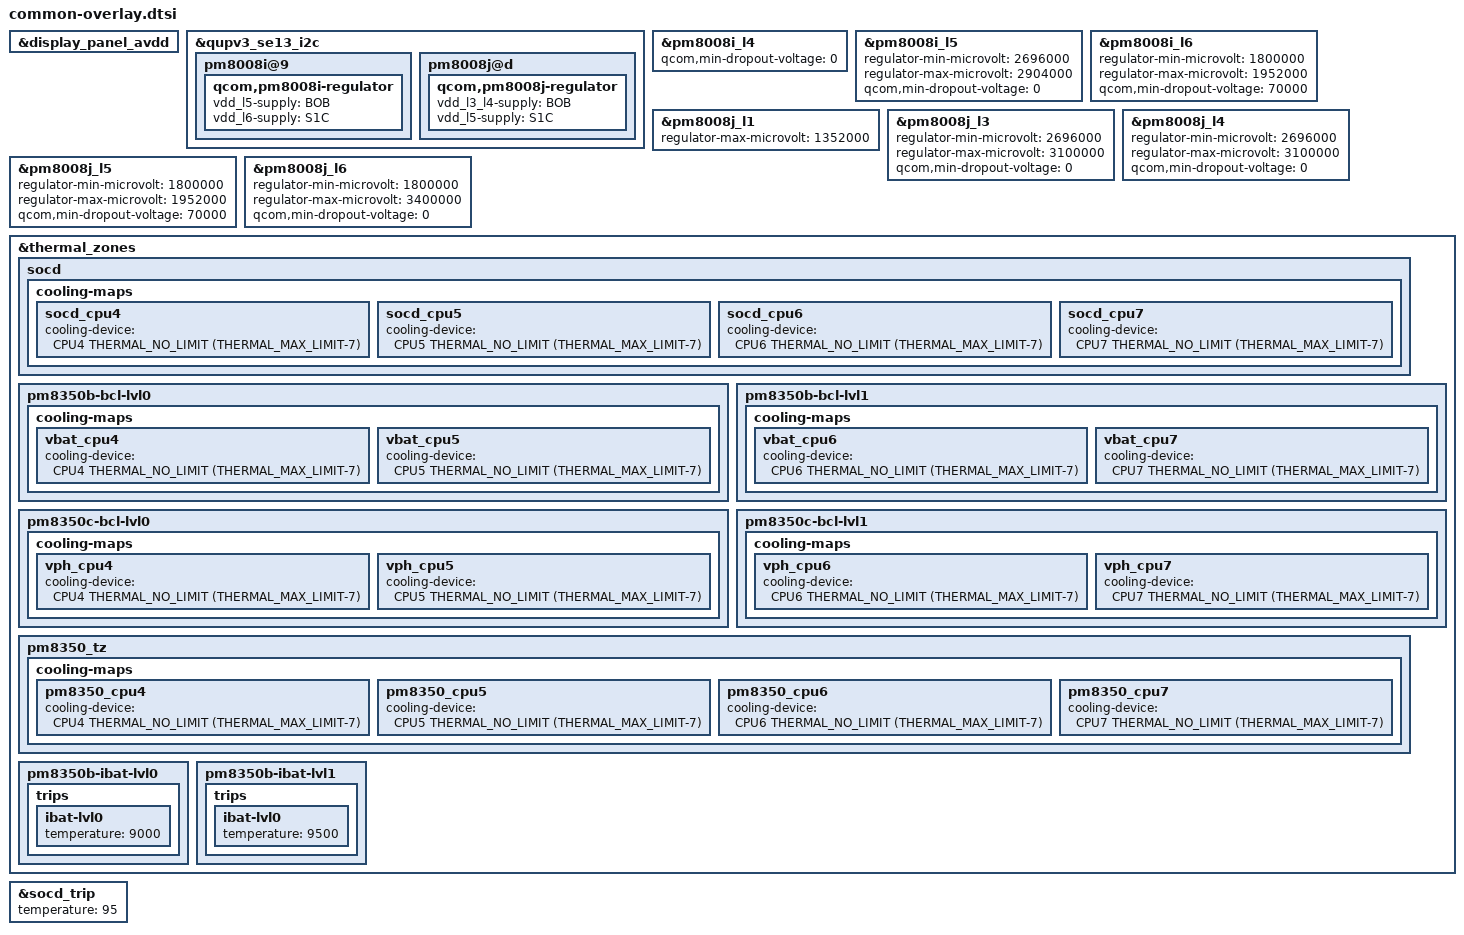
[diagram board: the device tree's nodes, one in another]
/*
 * Common qcom dtsi overlay changes for Sake and Vodka platform
 */

&display_panel_avdd {
	/delete-property/ gpio;
	/delete-property/ pinctrl-names;
	/delete-property/ pinctrl-0;
};

&qupv3_se13_i2c {
	pm8008i@9 {
		qcom,pm8008i-regulator {
			vdd_l5-supply = <&BOB>;
			vdd_l6-supply = <&S1C>;
		};
	};

	pm8008j@d {
		qcom,pm8008j-regulator {
			vdd_l3_l4-supply = <&BOB>;
			vdd_l5-supply = <&S1C>;
		};
	};
};

&pm8008i_l4 {
	qcom,min-dropout-voltage = <0>;
};

&pm8008i_l5 {
	regulator-min-microvolt = <2696000>;
	regulator-max-microvolt = <2904000>;
	qcom,min-dropout-voltage = <0>;
};

&pm8008i_l6 {
	regulator-min-microvolt = <1800000>;
	regulator-max-microvolt = <1952000>;
	qcom,min-dropout-voltage = <70000>;
};

&pm8008j_l1 {
	regulator-max-microvolt = <1352000>;
};

&pm8008j_l3 {
	regulator-min-microvolt = <2696000>;
	regulator-max-microvolt = <3100000>;
	qcom,min-dropout-voltage = <0>;
};

&pm8008j_l4 {
	regulator-min-microvolt = <2696000>;
	regulator-max-microvolt = <3100000>;
	qcom,min-dropout-voltage = <0>;
};

&pm8008j_l5 {
	regulator-min-microvolt = <1800000>;
	regulator-max-microvolt = <1952000>;
	qcom,min-dropout-voltage = <70000>;
};

&pm8008j_l6 {
	regulator-min-microvolt = <1800000>;
	regulator-max-microvolt = <3400000>;
	qcom,min-dropout-voltage = <0>;
};

&thermal_zones {
	socd {
		cooling-maps {
			socd_cpu4 {
				cooling-device = <&CPU4 THERMAL_NO_LIMIT
								(THERMAL_MAX_LIMIT-7)>;
			};

			socd_cpu5 {
				cooling-device = <&CPU5 THERMAL_NO_LIMIT
								(THERMAL_MAX_LIMIT-7)>;
			};

			socd_cpu6 {
				cooling-device = <&CPU6 THERMAL_NO_LIMIT
								(THERMAL_MAX_LIMIT-7)>;
			};

			socd_cpu7 {
				cooling-device = <&CPU7 THERMAL_NO_LIMIT
								(THERMAL_MAX_LIMIT-7)>;
			};
		};
	};

	pm8350b-bcl-lvl0 {
		cooling-maps {
			vbat_cpu4 {
				cooling-device = <&CPU4 THERMAL_NO_LIMIT
						(THERMAL_MAX_LIMIT-7)>;
			};

			vbat_cpu5 {
				cooling-device =<&CPU5 THERMAL_NO_LIMIT
						(THERMAL_MAX_LIMIT-7)>;
			};
		};
	};

	pm8350b-bcl-lvl1 {
		cooling-maps {
			vbat_cpu6 {
				cooling-device = <&CPU6 THERMAL_NO_LIMIT
						(THERMAL_MAX_LIMIT-7)>;
			};

			vbat_cpu7 {
				cooling-device = <&CPU7 THERMAL_NO_LIMIT
						(THERMAL_MAX_LIMIT-7)>;
			};
		};
	};

	pm8350c-bcl-lvl0 {
		cooling-maps {
			vph_cpu4 {
				cooling-device = <&CPU4 THERMAL_NO_LIMIT
						(THERMAL_MAX_LIMIT-7)>;
			};

			vph_cpu5 {
				cooling-device = <&CPU5 THERMAL_NO_LIMIT
						(THERMAL_MAX_LIMIT-7)>;
			};
		};
	};

	pm8350c-bcl-lvl1 {
		cooling-maps {
			vph_cpu6 {
				cooling-device = <&CPU6 THERMAL_NO_LIMIT
						(THERMAL_MAX_LIMIT-7)>;
			};

			vph_cpu7 {
				cooling-device = <&CPU7 THERMAL_NO_LIMIT
						(THERMAL_MAX_LIMIT-7)>;
			};
		};
	};

	pm8350_tz {
		cooling-maps {
			pm8350_cpu4 {
				cooling-device = <&CPU4 THERMAL_NO_LIMIT
						(THERMAL_MAX_LIMIT-7)>;
			};

			pm8350_cpu5 {
				cooling-device =<&CPU5 THERMAL_NO_LIMIT
						(THERMAL_MAX_LIMIT-7)>;
			};

			pm8350_cpu6 {
				cooling-device = <&CPU6 THERMAL_NO_LIMIT
						(THERMAL_MAX_LIMIT-7)>;
			};

			pm8350_cpu7 {
				cooling-device = <&CPU7 THERMAL_NO_LIMIT
						(THERMAL_MAX_LIMIT-7)>;
			};
		};
	};

	pm8350b-ibat-lvl0 {
		trips {
			ibat-lvl0 {
				temperature = <9000>;
			};
		};
	};

	pm8350b-ibat-lvl1 {
		trips {
			ibat-lvl0 {
				temperature = <9500>;
			};
		};
	};
};

&socd_trip {
	temperature = <95>;
};
